# D1H register map
Vendor: Allwinner; File version: 1.0
Registers are 32-bit, read-write, reset 0x0 unless marked. A register's access mark holds for its fields unless they carry their own. Offsets are from the block's base; [hi:lo] are bit positions; {n}, {i} and the like mark numbered series; 'fields as' and 'values as' point back to an identical list.

## RTC — Real Time CLock
Base 0x07090000
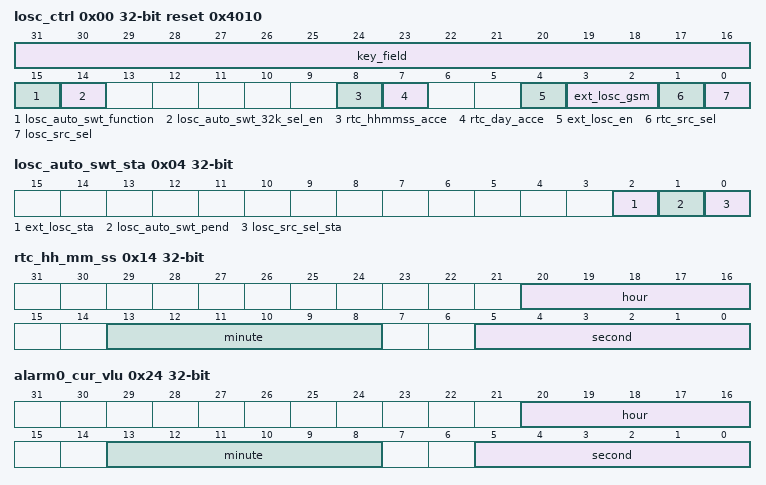
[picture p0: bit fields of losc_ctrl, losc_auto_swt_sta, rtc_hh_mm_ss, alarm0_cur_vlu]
0x00 losc_ctrl reset 0x4010 — Low Oscillator Control Register
  [31:16] key_field wo — Key Field . This field should be filled with 0x16AA, and then the bit0 and bit1 can be written with the new value.
  [15] losc_auto_swt_function — LOSC auto switch function disable
    0=ENABLE; 1=DISABLE
  [14] losc_auto_swt_32k_sel_en — LOSC auto switch 32K clk source select enable
    0=DISABLE (Disable. When the losc losts, the 32k clk source will not change to RC); 1=ENABLE (Enable. When the losc losts, the 32k clk source will change to RC (LOSC_SRC_SEL will be changed from 1 to 0))
  [8] rtc_hhmmss_acce — RTC Hour Minute Second access . After writing the RTC HH-MM-SS Register, this bit is set and it will be cleared until the real writing operation is finished. After writing the RTC HH-MM-SS Register, the RTC HH-MM-SS Register will be refreshed for at most one second. . Note: Make sure that the bit is 0 for time configuration.
  [7] rtc_day_acce — RTC DAY access . After writing the RTC DAY register, this bit is set and it will be cleared until the real writing operation is finished. After writing the RTC DAY register, the DAY register will be refreshed for at most one second. . Note: Make sure that the bit is 0 for time configuration.
  [4] ext_losc_en — External 32.768 kHz Crystal Enable
    0=DISABLE; 1=ENABLE
  [3:2] ext_losc_gsm — External 32.768 kHz Crystal GSM . When GSM is changed, the 32K oscillation circuit will arise transient instability. If the autoswitch function (bit 15) is enabled, 32K changes to RC16M with certain probability. The GSM can influence the time of 32K starting oscillation, the more the GSM, the shorter the time of starting oscillation. So modifying GSM is not recommended. . If you need to modify the GSM, firstly disable the auto switch function (bit 15), with a delay of 50 us, then change the GSM, the 32K clock source is changed to external clock.
    0=LOW; 3=HIGH
  [1] rtc_src_sel — RTC_TIMER Clock Source Select
    0=LOSC_SRC; 1=24MDIV32K (24MDIV32K . Before switching the bit, make sure that the 24MDIV32K function is enabled, that is, the bit16 of the 32K Fanout Control Register is 1.)
  [0] losc_src_sel — LOSC Clock Source Select
    0=LOW (Low frequency clock from 16M RC); 1=EXTERNAL (External 32.768 kHz OSC)
0x04 losc_auto_swt_sta — LOSC Auto Switch Status Register
  [2] ext_losc_sta ro — Work only when the auto switch function is enabled.
    0=NORMALLY (External 32.768 kHz OSC work normally); 1=ABNORMALLY (External 32.768 kHz OSC work abnormally)
  [1] losc_auto_swt_pend write-1-clears — LOSC auto switch pending
    0=NO_EFFECT; 1=AUTO (Auto switch pending, it means LOSC_SRC_SEL is changed from 1 to 0. . Setting 1 to this bit will clear it.)
  [0] losc_src_sel_sta ro — Checking LOSC clock source status
    values as losc_ctrl.losc_src_sel
0x08 intosc_clk_prescal reset 0xF — Internal OSC Clock Pre-scalar Register
  [4:0] intosc_32k_clk_prescal — Internal OSC 32K Clock Prescalar value N. . The clock output = Internal RC/32/N.
0x10 rtc_day — RTC Year-Month-Day Register
  [15:0] day — Set Day Range from 0 to 65535.
0x14 rtc_hh_mm_ss — RTC Hour-Minute-Second Register
  [20:16] hour — Set hour Range from 0 to 23.
  [13:8] minute — Set minute Range from 0 to 59.
  [5:0] second — Set second Range from 0 to 59.
0x20 alarm0_day_set — Alarm 0 Day Setting Register
  [15:0] alarm0_counter — Alarm 0 Counter is based on Day.
0x24 alarm0_cur_vlu — Alarm 0 Counter Current Value Register
  [20:16] hour — Current hour Range from 0 to 23.
  [13:8] minute — Current minute Range from 0 to 59.
  [5:0] second — Current second Range from 0 to 59.
0x28 alarm0_enable
  [0] alm_0_en — Alarm 0 Enable
    0=DISABLE; 1=ENABLE
0x2C alarm0_irq_en — Alarm 0 IRQ Enable Register
  [0] alarm0_irq_en — Alarm 0 IRQ Enable
    0=DISABLE; 1=ENABLE
0x30 alarm0_irq_sta — Alarm 0 IRQ Status Register
  [0] alarm0_irq_pend write-1-clears — Alarm 0 IRQ Pending bit
    0=NO_EFFECT; 1=PENDING (Pending, alarm 0 counter value is reached . If alarm 0 irq enable is set to 1, the pending bit will be sent to the interrupt controller.)
0x50 alarm_config — Alarm Configuration Register
  [0] alarm_wakeup — Configuration of alarm wake up output.
    0=DISABLE (Disable alarm wake up output); 1=ENABLE (Enable alarm wake up output)
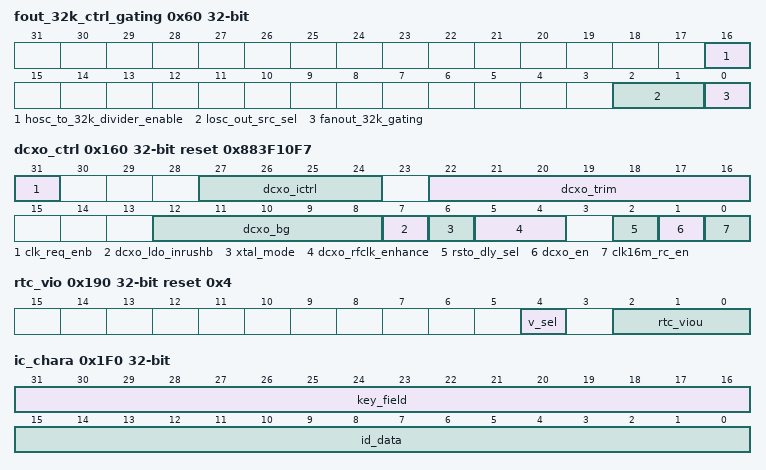
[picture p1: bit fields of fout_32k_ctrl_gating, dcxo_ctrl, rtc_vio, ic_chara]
0x60 fout_32k_ctrl_gating — 32K Fanout Control Gating Register
  [16] hosc_to_32k_divider_enable
    0=DISABLE (Disable the hosc 24M to 32K divider circuit); 1=ENABLE (Enable the hosc 24M to 32K divider circuit)
  [2:1] losc_out_src_sel — LOSC output source select
    0=RTC_32K (RTC_32K (select by RC_CLK_SRC_SEL LOSC_SRC_SEL)); 1=LOSC; 2=HOSC (HOSC divided 32K)
  [0] fanout_32k_gating — LOSC out gating enable . Configuration of LOSC output, and there is no LOSC output by default.
    0=MASK (Mask LOSC output gating); 1=ENABLE (Enable LOSC output gating)
{0x100+4i} gp_data{i} (i=0..7) — General Purpose Register
  [31:0] gp_data
{0x120+4i} fboot_info{i} (i=0..1) — Fast Boot Information Register [01]
  [31:0] fboot_info — Fast Boot Information [i], refer to BROM spec.
0x160 dcxo_ctrl reset 0x883F10F7 — DCXO Control Register
  [31] clk_req_enb — Clock REQ enable
    0=ENABLE (Enable DCXO wake up function); 1=DISABLE (Disable DCXO wake up function)
  [27:24] dcxo_ictrl — DCXO current control value
  [22:16] dcxo_trim — DCXO cap array value . The capacity cell is 55 fF.
  [12:8] dcxo_bg — DCXO bandgap output voltage
  [7] dcxo_ldo_inrushb — DCXO LDO driving capacity signal, active high
  [6] xtal_mode — Xtal mode enable signal, active high
    0=FOR_EXTERNAL (For external clk input mode); 1=FOR_NORMAL_MODE
  [5:4] dcxo_rfclk_enhance — DCXO rfclk enhance . Enhance driving capacity of output OUT_RF_REFCLK, 0x0 for 5 pF, 0x1 for 10 pF, 0x2 for 15 pF, 0x3 for 20 pF.
  [2] rsto_dly_sel — For Debug Use Only. . It cannot configure to 0 in normal state.
  [1] dcxo_en — DCXO enable
    1=ENABLE; 0=DISABLE
  [0] clk16m_rc_en — The related register configuration is necessary to ensure the reset debounce circuit has a stable clock source. The first time SoC starts up, by default, the reset debounce circuit of SoC uses 32K divided by RC16M. In power-off, software reads the related bit to ensure whether EXT32K is working normally, if it is normal, first switch the clock source of debounce circuit to EXT32K, then close RC16M. Without EXT32K scenario or external RTC scenario, software confirms firstly whether EXT32K is working normally before switching, or software does not close RC16M.
    1=ENABLE; 0=DISABLE
0x190 rtc_vio reset 0x4 — RTC_VIO Regulation Register
  [4] v_sel — VDD Select
    0=RESISTANCE (Resistance divider); 1=BAND (Band gap)
  [2:0] rtc_viou — RTC_VIO Voltage Select . The RTC-VIO is provided power for RTC digital part. . These bits are useful for regulating the RTC_VIO from 0.65 V to 1.3 V.
    0=V_1_0 (1.0 V); 1=V_0_65 (0.65 V (the configuration can cause RTC reset)); 2=V_0_7 (0.7 V); 3=V_0_8 (0.8 V); 4=V_0_9 (0.9 V); 5=V_1_1 (1.1 V); 6=V_1_2 (1.2 V); 7=V_1_3 (1.3 V)
0x1F0 ic_chara — IC Characteristic Register
  [31:16] key_field — Key Field . The field should be written as 0x16AA. Writing any other value in this field aborts the write-operation.
  [15:0] id_data — Return 0x16AA only if the KEY_FIELD is set as 0x16AA when read those bits, otherwise return 0x0.
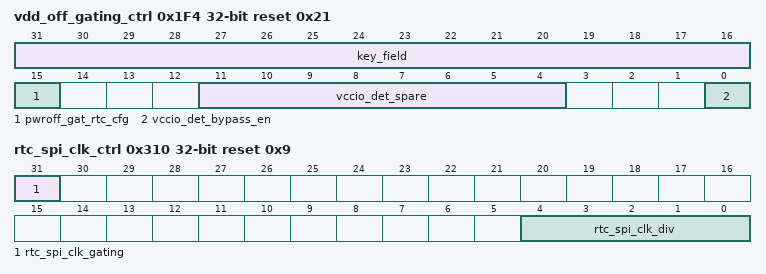
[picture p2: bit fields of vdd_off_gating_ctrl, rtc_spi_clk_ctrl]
0x1F4 vdd_off_gating_ctrl reset 0x21 — VDD Off Gating Control Register
  [31:16] key_field wo — Key Field . This field should be filled with 0x16AA, and then the bit 15 can be configured.
  [15] pwroff_gat_rtc_cfg wo — Power off gating control signal (For Debug Use Only) . When use vdd_sys to RTC isolation software control, write this bit to 1. It will only be cleared by resetb release.
  [11:4] vccio_det_spare — - Bit[7:5]: Reserved, default=0 - Bit[4]: Bypass debounce circuit, defaule=0 - Bit[3]: Enable control, defaule=0 - 0: Disable VCC-IO detection - 1: Force the detection output - Bit[2:0]: Gear adjustment - 000: Detection threshold is 2.5 V - 001: Detection threshold is 2.6 V - 010: Detection threshold is 2.7 V (default) - 011: Detection threshold is 2.8 V - 100: Detection threshold is 2.9 V - 101: Detection threshold is 3 V - 110: N/A - 111: N/A
  [0] vccio_det_bypass_en
    0=NOT_BYPASS; 1=BYPASS
0x204 efuse_hv_pwrswt_ctrl — Efuse High Voltage Power Switch Control Register
  [0] efuse_1_8v_power_switch_control — 1: Open power switch 0: Close power switch
    1=OPEN (Open power switch); 0=CLOSE (Close power switch)
0x310 rtc_spi_clk_ctrl reset 0x9 — RTC SPI Clock Control Register
  [31] rtc_spi_clk_gating — RTC Reg CFG SPI Clock Gating . Before configurating RTC register, the clock divider of SPI needs be configured firstly, then clock gating needs be enabled. . Note: Frequency division and clock gating can not be set at the same time.
    0=GATING; 1=NOT_GATING
  [4:0] rtc_spi_clk_div — RTC Reg CFG SPI Clock Divider: M . Actual SPI Clock = AHBS1/(M+1), (0 to 15) The default frequency of AHBS1 is 200 MHz, and the default frequency of SPI Clock is 20 MHz. . Note: The SPI clock can not exceed 50 MHz, or else the RTC register may be abnormal.
